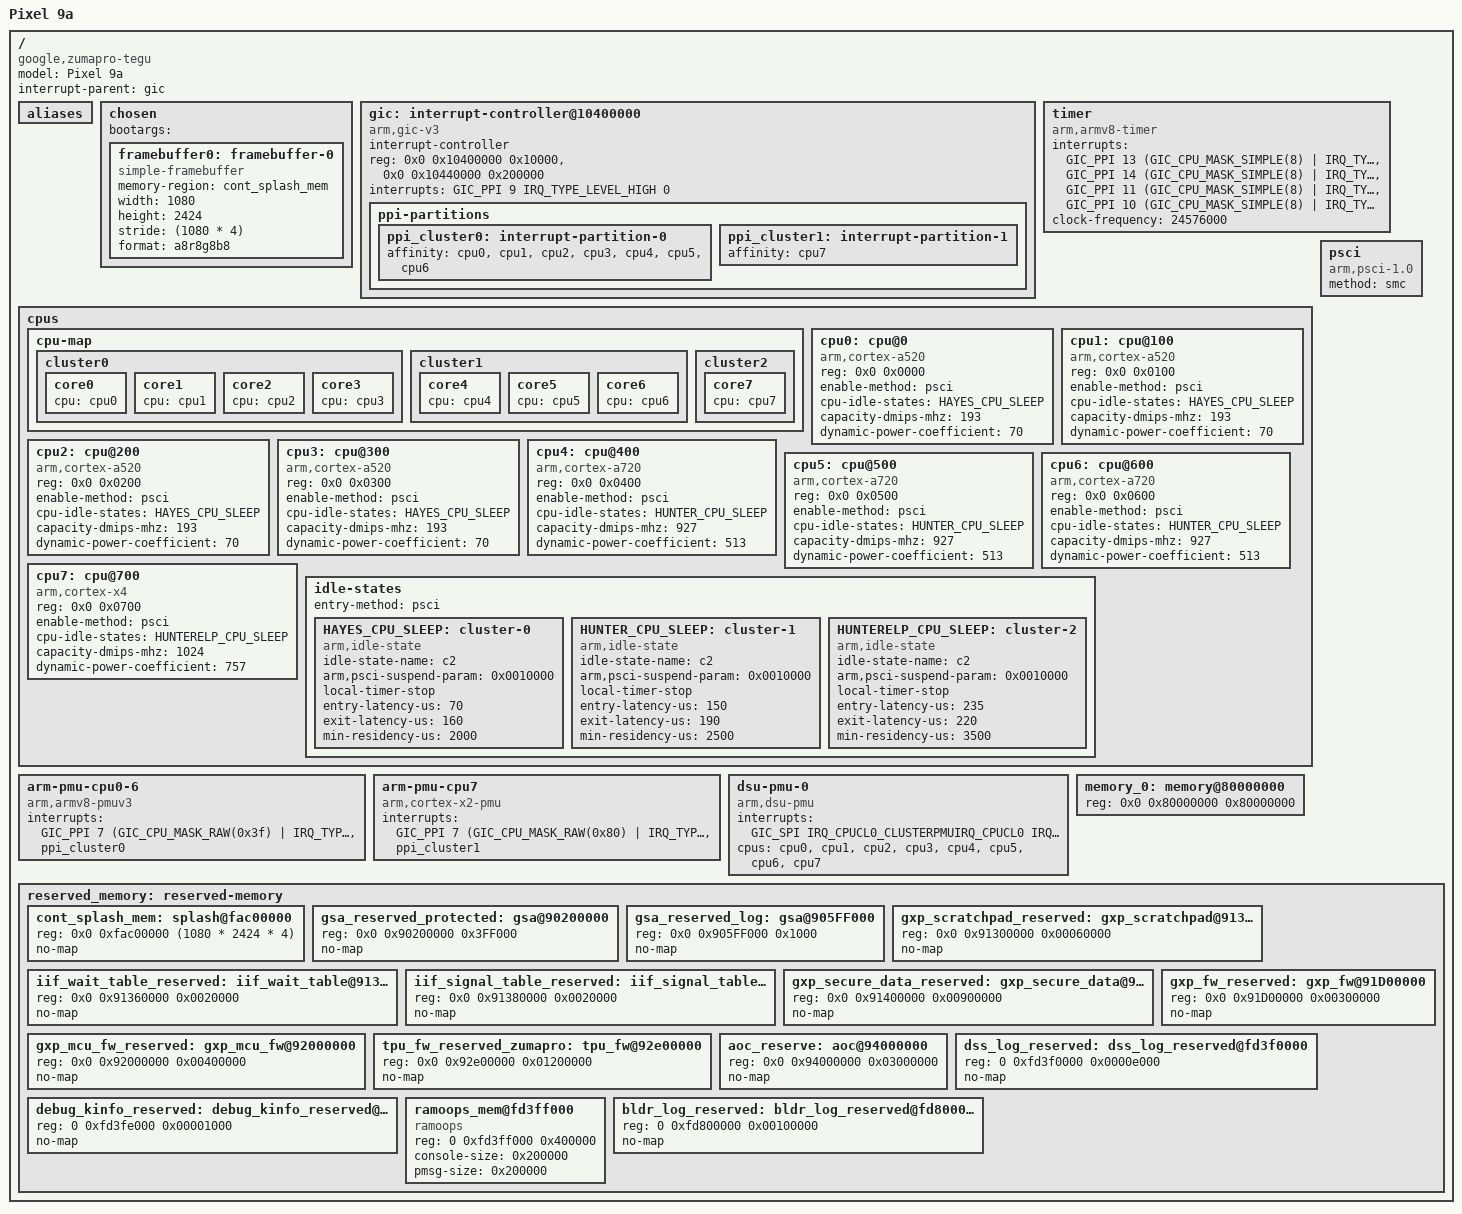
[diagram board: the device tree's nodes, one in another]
// SPDX-License-Identifier: GPL-2.0-only
/*
 * Copyright 2022 Google LLC.
 *
 */

/dts-v1/;

#include <dt-bindings/interrupt-controller/arm-gic.h>
#include <dt-bindings/interrupt-controller/zumapro.h>
#include "zumapro-pinctrl.dtsi"

/ {

	model = "Pixel 9a";
	compatible = "google,zumapro-tegu", "google,zumapro";
	interrupt-parent = <&gic>;
	#address-cells = <2>;
	#size-cells = <1>;

	aliases {
	};

	chosen {
		/* Bootloader expects bootargs specified otherwise it crashes */
		bootargs = "";
		//stdout-path = &serial_0;

		/* Use display framebuffer as setup by bootloader */
		framebuffer0: framebuffer-0 {
			compatible = "simple-framebuffer";
			memory-region = <&cont_splash_mem>;
			// format properties to be added by actual board
			status = "disabled";
		};
	};

	gic: interrupt-controller@10400000 {
		compatible = "arm,gic-v3";
		#interrupt-cells = <4>;
		interrupt-controller;
		reg = <0x0 0x10400000 0x10000>,		/* GICD */
		<0x0 0x10440000 0x200000>;	/* GICR * 8 */
		interrupts = <GIC_PPI 9 IRQ_TYPE_LEVEL_HIGH 0>;

		ppi-partitions {
			ppi_cluster0: interrupt-partition-0 {
				affinity = <&cpu0 &cpu1 &cpu2 &cpu3 &cpu4 &cpu5 &cpu6>;
			};

			ppi_cluster1: interrupt-partition-1 {
				affinity = <&cpu7>;
			};
		};
	};

	timer {
		compatible = "arm,armv8-timer";
		interrupts = <GIC_PPI 13 (GIC_CPU_MASK_SIMPLE(8) | IRQ_TYPE_LEVEL_LOW) 0>,
		<GIC_PPI 14 (GIC_CPU_MASK_SIMPLE(8) | IRQ_TYPE_LEVEL_LOW) 0>,
		<GIC_PPI 11 (GIC_CPU_MASK_SIMPLE(8) | IRQ_TYPE_LEVEL_LOW) 0>,
		<GIC_PPI 10 (GIC_CPU_MASK_SIMPLE(8) | IRQ_TYPE_LEVEL_LOW) 0>;
		clock-frequency = <24576000>;
	};

	/*clock: clock-controller@26040000 {
		compatible = "google,zuma-clock";
		reg = <0x0 0x26040000 0x8000>;
		#clock-cells = <1>;
		acpm-ipc-channel = <0>;
	};*/


	cpus {
		#address-cells = <2>;
		#size-cells = <0>;

		#define CPU_CL0 "0-3"
		#define CPU_CL1 "4-6"
		#define CPU_CL2 "7"
		#define CPU_ALL "0-7"

		cpu-map {
			cluster0 {
				core0 {
					cpu = <&cpu0>;
				};
				core1 {
					cpu = <&cpu1>;
				};
				core2 {
					cpu = <&cpu2>;
				};
				core3 {
					cpu = <&cpu3>;
				};
			};
			cluster1 {
				core4 {
					cpu = <&cpu4>;
				};
				core5 {
					cpu = <&cpu5>;
				};
				core6 {
					cpu = <&cpu6>;
				};
			};
			cluster2 {
				core7 {
					cpu = <&cpu7>;
				};
			};
		};

		cpu0: cpu@0 {
			device_type = "cpu";
			compatible = "arm,cortex-a520"; // android uses arm,armv9.2?? It's not in the kernel sources...
			reg = <0x0 0x0000>;
			enable-method = "psci";
			cpu-idle-states =  <&HAYES_CPU_SLEEP>;
			capacity-dmips-mhz = <193>;
			dynamic-power-coefficient = <70>;
		};
		cpu1: cpu@100 {
			device_type = "cpu";
			compatible = "arm,cortex-a520"; // android uses arm,armv9.2?? It's not in the kernel sources...
			reg = <0x0 0x0100>;
			enable-method = "psci";
			cpu-idle-states =  <&HAYES_CPU_SLEEP>;
			capacity-dmips-mhz = <193>;
			dynamic-power-coefficient = <70>;
		};
		cpu2: cpu@200 {
			device_type = "cpu";
			compatible = "arm,cortex-a520"; // android uses arm,armv9.2?? It's not in the kernel sources...
			reg = <0x0 0x0200>;
			enable-method = "psci";
			cpu-idle-states =  <&HAYES_CPU_SLEEP>;
			capacity-dmips-mhz = <193>;
			dynamic-power-coefficient = <70>;
		};
		cpu3: cpu@300 {
			device_type = "cpu";
			compatible = "arm,cortex-a520"; // android uses arm,armv9.2?? It's not in the kernel sources...
			reg = <0x0 0x0300>;
			enable-method = "psci";
			cpu-idle-states =  <&HAYES_CPU_SLEEP>;
			capacity-dmips-mhz = <193>;
			dynamic-power-coefficient = <70>;
		};
		cpu4: cpu@400 {
			device_type = "cpu";
			compatible = "arm,cortex-a720"; // android uses arm,armv9.2?? It's not in the kernel sources...
			reg = <0x0 0x0400>;
			enable-method = "psci";
			cpu-idle-states =  <&HUNTER_CPU_SLEEP>;
			capacity-dmips-mhz = <927>;
			dynamic-power-coefficient = <513>;
		};
		cpu5: cpu@500 {
			device_type = "cpu";
			compatible = "arm,cortex-a720"; // android uses arm,armv9.2?? It's not in the kernel sources...
			reg = <0x0 0x0500>;
			enable-method = "psci";
			cpu-idle-states =  <&HUNTER_CPU_SLEEP>;
			capacity-dmips-mhz = <927>;
			dynamic-power-coefficient = <513>;
		};
		cpu6: cpu@600 {
			device_type = "cpu";
			compatible = "arm,cortex-a720"; // android uses arm,armv9.2?? It's not in the kernel sources...
			reg = <0x0 0x0600>;
			enable-method = "psci";
			cpu-idle-states =  <&HUNTER_CPU_SLEEP>;
			capacity-dmips-mhz = <927>;
			dynamic-power-coefficient = <513>;
		};
		cpu7: cpu@700 {
			device_type = "cpu";
			compatible = "arm,cortex-x4"; // android uses arm,armv9.2?? It's not in the kernel sources...
			reg = <0x0 0x0700>;
			enable-method = "psci";
			cpu-idle-states =  <&HUNTERELP_CPU_SLEEP>;
			capacity-dmips-mhz = <1024>;
			dynamic-power-coefficient = <757>;
		};

		idle-states {
			entry-method = "psci";
			HAYES_CPU_SLEEP: cluster-0 { // a520; hayes-cpu-sleep on android
				idle-state-name = "c2";
				compatible = "arm,idle-state";
				arm,psci-suspend-param = <0x0010000>;
				local-timer-stop;
				entry-latency-us = <70>;
				exit-latency-us = <160>;
				min-residency-us = <2000>;
				status = "okay";
			};
			HUNTER_CPU_SLEEP: cluster-1 { // a720; hunter-cpu-sleep on android
				idle-state-name = "c2";
				compatible = "arm,idle-state";
				arm,psci-suspend-param = <0x0010000>;
				local-timer-stop;
				entry-latency-us = <150>;
				exit-latency-us = <190>;
				min-residency-us = <2500>;
				status = "okay";
			};
			HUNTERELP_CPU_SLEEP: cluster-2 { // x4; hunterelp-cpu-sleep on android
				idle-state-name = "c2";
				compatible = "arm,idle-state";
				arm,psci-suspend-param = <0x0010000>;
				local-timer-stop;
				entry-latency-us = <235>;
				exit-latency-us = <220>;
				min-residency-us = <3500>;
				status = "okay";
			};
		};
	};

	psci {
		compatible = "arm,psci-1.0";
		method = "smc";
		status = "okay";
	};

	// I have no idea why android uses wrong pmus?
	arm-pmu-cpu0-6 {
		compatible = "arm,armv8-pmuv3";
		interrupts = <GIC_PPI 7 (GIC_CPU_MASK_RAW(0x3f) | IRQ_TYPE_LEVEL_HIGH) &ppi_cluster0>;
	};

	arm-pmu-cpu7 {
		compatible = "arm,cortex-x2-pmu";
		interrupts = <GIC_PPI 7 (GIC_CPU_MASK_RAW(0x80) | IRQ_TYPE_LEVEL_HIGH) &ppi_cluster1>;
	};

	// This might be running without a diver in android???
	/*pmu_system_controller: system-controller@15460000 {
		compatible = "samsung,gs101-pmu", "syscon";
		reg = <0x0 0x15460000 0x10000>;
	};*/

	dsu-pmu-0 {
		compatible = "arm,dsu-pmu";
		interrupts = <GIC_SPI IRQ_CPUCL0_CLUSTERPMUIRQ_CPUCL0 IRQ_TYPE_LEVEL_HIGH 0>;
		cpus = <&cpu0>, <&cpu1>, <&cpu2>, <&cpu3>, <&cpu4>, <&cpu5>, <&cpu6>, <&cpu7>;
	};

	memory_0: memory@80000000 {
		device_type = "memory";
		reg = <0x0 0x80000000 0x80000000>;
		//phandle = <0x388>;
	};

	reserved_memory: reserved-memory {
		#address-cells = <2>;
		#size-cells = <1>;
		ranges;

		cont_splash_mem: splash@fac00000 {
			/* size to be updated by actual board */
			reg = <0x0 0xfac00000 0x0>;
			no-map;
			status = "disabled";
		};


		/*ect_binary: ect_binary {
			compatible = "exynos,ect_rmem";
			reg = <0x0 0x90000000 0x00060000>;
		};*/

		gsa_reserved_protected: gsa@90200000 {
			reg = <0x0 0x90200000 0x3FF000>;
			no-map;
		};

		gsa_reserved_log: gsa@905FF000 {
			reg = <0x0 0x905FF000 0x1000>;
			no-map;
		};

		gxp_scratchpad_reserved: gxp_scratchpad@91300000 {
			reg = <0x0 0x91300000 0x00060000>;
			no-map;
		};

		iif_wait_table_reserved: iif_wait_table@91360000 {
			reg = <0x0 0x91360000 0x0020000>;
			no-map;
		};

		iif_signal_table_reserved: iif_signal_table@91380000 {
			reg = <0x0 0x91380000 0x0020000>;
			no-map;
		};

		gxp_secure_data_reserved: gxp_secure_data@91400000 {
			reg = <0x0 0x91400000 0x00900000>;
			no-map;
		};

		gxp_fw_reserved: gxp_fw@91D00000 {
			reg = <0x0 0x91D00000 0x00300000>;
			no-map;
		};

		gxp_mcu_fw_reserved: gxp_mcu_fw@92000000 {
			reg = <0x0 0x92000000 0x00400000>;
			no-map;
		};

		tpu_fw_reserved_zumapro: tpu_fw@92e00000 {
			reg = <0x0 0x92e00000 0x01200000>;
			no-map;
		};

		aoc_reserve: aoc@94000000 {
			reg = <0x0 0x94000000 0x03000000>;
			no-map;
		};

		dss_log_reserved: dss_log_reserved@fd3f0000 {
			reg = <0 0xfd3f0000 0x0000e000>;
			no-map;
		};

		debug_kinfo_reserved: debug_kinfo_reserved@fd3fe000 {
			reg = <0 0xfd3fe000 0x00001000>;
			no-map;
		};

		ramoops_mem@fd3ff000 {
			compatible = "ramoops";
			reg = <0 0xfd3ff000 0x400000>;
			console-size = <0x200000>;
			pmsg-size = <0x200000>;
		};

		bldr_log_reserved: bldr_log_reserved@fd800000 {
			reg = <0 0xfd800000 0x00100000>;
			no-map;
		};

		/*cp_rmem: cp_rmem {
			compatible = "exynos,modem_if";
			reg = <0x0 0xEA400000 0x00C00000>;
			rmem_index = <0>;
		};

		cp_msi_rmem: cp_msi_rmem {
			compatible = "exynos,modem_if";
			reg = <0x0 0xF6200000 0x00001000>;
			rmem_index = <1>;
		};

		cp_rmem_1: cp_rmem_1 {
			compatible = "exynos,modem_if";
			reg = <0x0 0xE8000000 0x02000000>;
			rmem_index = <2>;
		};

		cp_aoc_rmem: cp_aoc_rmem {
			compatible = "exynos,modem_if";
			reg = <0x0 0x197FD000 0x00003000>;
			rmem_index = <3>;
		};*/


		/* begin debug_snapshot rmem section */
		/*header: header {
			reg = <0 DSS_HEADER_ADDR DSS_HEADER_SIZE>;
			no-map;
		};

		log_kevents: log_kevents {
			reg = <0 DSS_LOG_KEVENTS_ADDR
			DSS_LOG_KEVENTS_SIZE>;
			no-map;
		};

		log_bcm: log_bcm {
			reg = <0 DSS_LOG_BCM_ADDR DSS_LOG_BCM_SIZE>;
			no-map;
		};

		log_s2d: log_s2d {
			reg = <0 DSS_LOG_S2D_ADDR DSS_LOG_S2D_SIZE>;
			no-map;
		};

		log_arrdumpreset: log_array_reset {
			reg = <0 DSS_LOG_ARRAYRESET_ADDR
			DSS_LOG_ARRAYRESET_SIZE>;
			no-map;
		};

		log_arrdumppanic: log_array_panic {
			reg = <0 DSS_LOG_ARRAYPANIC_ADDR
			DSS_LOG_ARRAYPANIC_SIZE>;
			no-map;
		};

		log_slcdump: log_slcdump {
			reg = <0 DSS_LOG_SLCDUMP_ADDR
			DSS_LOG_SLCDUMP_SIZE>;
			no-map;
		};

		log_preslcdump: log_preslcdump {
			reg = <0 DSS_LOG_PRE_SLCDUMP_ADDR
			DSS_LOG_SLCDUMP_SIZE>;
			no-map;
		};

		log_itmon: log_itmon {
			reg = <0 DSS_LOG_ITMON_ADDR DSS_LOG_ITMON_SIZE>;
			no-map;
		};

		log_s2d_extract: log_s2d_extract {
			reg = <0 DSS_LOG_S2D_EXTRACT_ADDR
			DSS_LOG_S2D_EXTRACT_SIZE>;
			no-map;
		};*/
		/* end debug_memory rmem section */

		/*seclog_mem: seclog_mem {
			compatible = "exynos,seclog";
			reg = <0 SECLOG_LOG_BUF_BASE SECLOG_LOG_BUF_TOTAL_SIZE>;
		};*/
	};
};

&cont_splash_mem {
	reg = <0x0 0xfac00000 (1080 * 2424 * 4)>;
	status = "okay";
};

&framebuffer0 {
	width = <1080>;
	height = <2424>;
	stride = <(1080 * 4)>;
	format = "a8r8g8b8";
	status = "okay";
};
